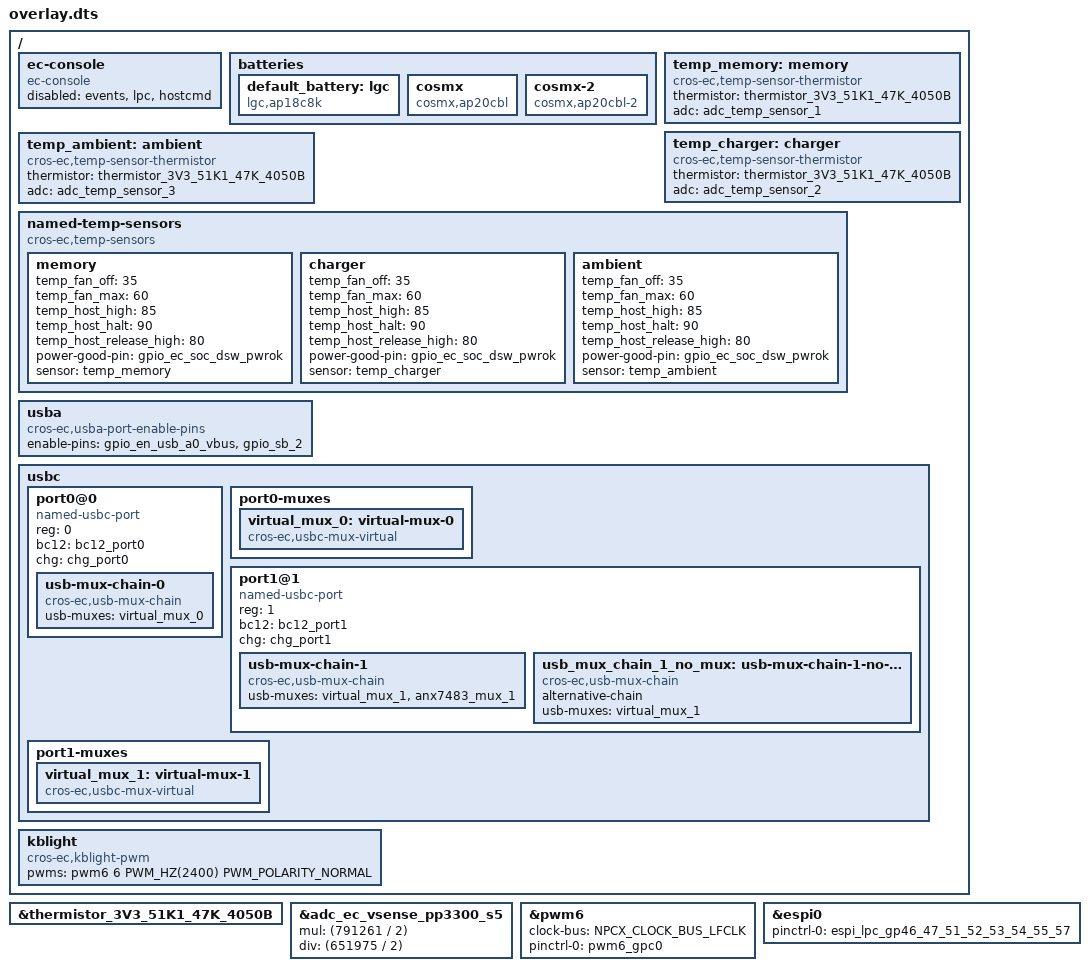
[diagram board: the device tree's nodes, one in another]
/* Copyright 2022 The ChromiumOS Authors
 * Use of this source code is governed by a BSD-style license that can be
 * found in the LICENSE file.
 */

#include <cros/thermistor/thermistor.dtsi>

/ {
	ec-console {
		compatible = "ec-console";
		disabled = "events", "lpc", "hostcmd";
	};

	batteries {
		default_battery: lgc {
			compatible = "lgc,ap18c8k", "battery-smart";
		};
		cosmx {
			compatible = "cosmx,ap20cbl", "battery-smart";
		};
		cosmx-2 {
			compatible = "cosmx,ap20cbl-2", "battery-smart";
		};
	};

	temp_memory: memory {
		compatible = "cros-ec,temp-sensor-thermistor";
		thermistor = <&thermistor_3V3_51K1_47K_4050B>;
		adc = <&adc_temp_sensor_1>;
	};
	temp_charger: charger {
		compatible = "cros-ec,temp-sensor-thermistor";
		thermistor = <&thermistor_3V3_51K1_47K_4050B>;
		adc = <&adc_temp_sensor_2>;
	};
	temp_ambient: ambient {
		compatible = "cros-ec,temp-sensor-thermistor";
		thermistor = <&thermistor_3V3_51K1_47K_4050B>;
		adc = <&adc_temp_sensor_3>;
	};

	named-temp-sensors {
		compatible = "cros-ec,temp-sensors";
		memory {
			temp_fan_off = <35>;
			temp_fan_max = <60>;
			temp_host_high = <85>;
			temp_host_halt = <90>;
			temp_host_release_high = <80>;
			power-good-pin = <&gpio_ec_soc_dsw_pwrok>;
			sensor = <&temp_memory>;
		};
		charger {
			temp_fan_off = <35>;
			temp_fan_max = <60>;
			temp_host_high = <85>;
			temp_host_halt = <90>;
			temp_host_release_high = <80>;
			power-good-pin = <&gpio_ec_soc_dsw_pwrok>;
			sensor = <&temp_charger>;
		};
		ambient {
			temp_fan_off = <35>;
			temp_fan_max = <60>;
			temp_host_high = <85>;
			temp_host_halt = <90>;
			temp_host_release_high = <80>;
			power-good-pin = <&gpio_ec_soc_dsw_pwrok>;
			sensor = <&temp_ambient>;
		};
	};

	usba {
		compatible = "cros-ec,usba-port-enable-pins";
		/*
		 * sb_2 is only configured as GPIO when USB-A1 is present,
		 * but it's still safe to control when disabled.
		 *
		 * ILIM_SEL pins are referred to by legacy enum name,
		 * GPIO_USB*_ILIM_SEL. The one for port A1 is unused on
		 * sub-boards that don't have USB-A so is safe to control
		 * regardless of system configuration.
		 */
		enable-pins = <&gpio_en_usb_a0_vbus &gpio_sb_2>;
		status = "okay";
	};

	usbc {
		#address-cells = <1>;
		#size-cells = <0>;

		port0@0 {
			compatible = "named-usbc-port";
			reg = <0>;
			bc12 = <&bc12_port0>;
			chg = <&chg_port0>;
			usb-mux-chain-0 {
				compatible = "cros-ec,usb-mux-chain";
				usb-muxes = <&virtual_mux_0>;
			};
		};
		port0-muxes {
			virtual_mux_0: virtual-mux-0 {
				compatible = "cros-ec,usbc-mux-virtual";
			};
		};
		/*
		 * TODO(b:211693800): port1 may not be present on some
		 * sub-boards.
		 */
		port1@1 {
			compatible = "named-usbc-port";
			reg = <1>;
			bc12 = <&bc12_port1>;
			chg = <&chg_port1>;
			usb-mux-chain-1 {
				compatible = "cros-ec,usb-mux-chain";
				usb-muxes = <&virtual_mux_1 &anx7483_mux_1>;
			};
			usb_mux_chain_1_no_mux: usb-mux-chain-1-no-mux {
				compatible = "cros-ec,usb-mux-chain";
				alternative-chain;
				usb-muxes = <&virtual_mux_1>;
			};
		};
		port1-muxes {
			virtual_mux_1: virtual-mux-1 {
				compatible = "cros-ec,usbc-mux-virtual";
			};
		};
	};

	kblight {
		compatible = "cros-ec,kblight-pwm";
		pwms = <&pwm6 6 PWM_HZ(2400) PWM_POLARITY_NORMAL>;
	};
};

&thermistor_3V3_51K1_47K_4050B {
	status = "okay";
};

&adc_ec_vsense_pp3300_s5 {
	/*
	 * Voltage divider on input has 47k upper and 220k lower legs with
	 * 2714 mV full-scale reading on the ADC. Apply the largest possible
	 * multiplier (without overflowing int32) to get the best possible
	 * approximation of the actual ratio, but derate by a factor of two to
	 * ensure unexpectedly high values won't overflow.
	 */
	mul = <(791261 / 2)>;
	div = <(651975 / 2)>;
};

&pwm6 {
	status = "okay";
	clock-bus = "NPCX_CLOCK_BUS_LFCLK";
	pinctrl-0 = <&pwm6_gpc0>;
	pinctrl-names = "default";
};

/* host interface */
&espi0 {
	status = "okay";
	pinctrl-0 = <&espi_lpc_gp46_47_51_52_53_54_55_57>;
	pinctrl-names = "default";
};
